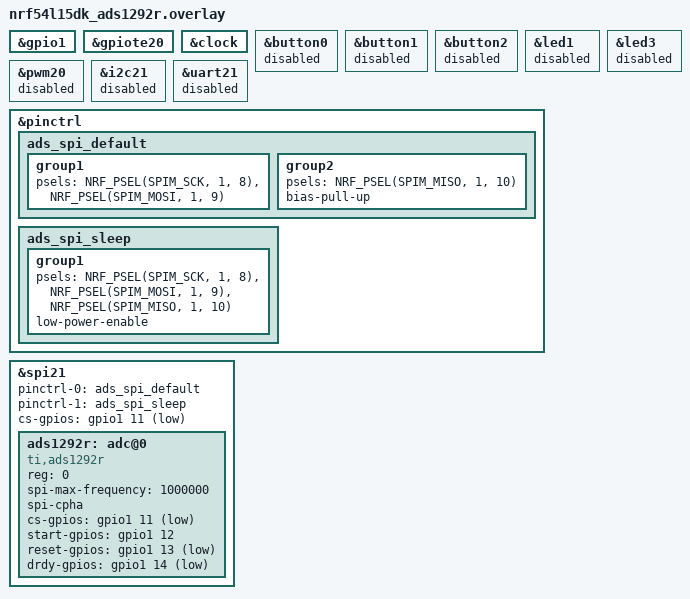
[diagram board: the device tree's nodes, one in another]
#include <zephyr/dt-bindings/gpio/gpio.h>
#include <zephyr/dt-bindings/pinctrl/nrf-pinctrl.h>

/*
 * ADS1292R full test-signal wiring for the Nordic nRF54L15 DK.
 *
 * Configure the DK target voltage to 3V3 in Nordic Board Programmer before
 * connecting the ADS1292R logic pins.
 *
 *   ADS SCK        -> P1.08
 *   ADS DIN/MOSI   -> P1.09
 *   ADS DOUT/MISO  -> P1.10
 *   ADS CS         -> P1.11
 *   ADS START      -> P1.12
 *   ADS PWDN/RESET -> P1.13
 *   ADS DRDY       -> P1.14
 */

&gpio1 { status = "okay"; };
&gpiote20 { status = "okay"; };
&clock { status = "okay"; };

/* These DK functions use pins selected above for ADS signals. */
&button0 { status = "disabled"; };  /* P1.13 / ADS PWDN/RESET */
&button1 { status = "disabled"; };  /* P1.09 / ADS DIN/MOSI */
&button2 { status = "disabled"; };  /* P1.08 / ADS SCK */
&led1 { status = "disabled"; };     /* P1.10 / ADS DOUT/MISO */
&led3 { status = "disabled"; };     /* P1.14 / ADS DRDY */
&pwm20 { status = "disabled"; };

/* spi21 shares this serial block with i2c21/uart21. Keep the owner explicit. */
&i2c21 { status = "disabled"; };
&uart21 { status = "disabled"; };

&pinctrl {
    ads_spi_default: ads_spi_default {
        group1 {
            psels = <NRF_PSEL(SPIM_SCK, 1, 8)>,
                    <NRF_PSEL(SPIM_MOSI, 1, 9)>;
        };
        group2 {
            psels = <NRF_PSEL(SPIM_MISO, 1, 10)>;
            bias-pull-up;
        };
    };

    ads_spi_sleep: ads_spi_sleep {
        group1 {
            psels = <NRF_PSEL(SPIM_SCK, 1, 8)>,
                    <NRF_PSEL(SPIM_MOSI, 1, 9)>,
                    <NRF_PSEL(SPIM_MISO, 1, 10)>;
            low-power-enable;
        };
    };
};

&spi21 {
    status = "okay";
    pinctrl-0 = <&ads_spi_default>;
    pinctrl-1 = <&ads_spi_sleep>;
    pinctrl-names = "default", "sleep";
    cs-gpios = <&gpio1 11 GPIO_ACTIVE_LOW>;

    ads1292r: adc@0 {
        compatible = "ti,ads1292r";
        reg = <0>;
        spi-max-frequency = <1000000>;
        spi-cpha;
        cs-gpios = <&gpio1 11 GPIO_ACTIVE_LOW>;
        start-gpios = <&gpio1 12 GPIO_ACTIVE_HIGH>;
        reset-gpios = <&gpio1 13 GPIO_ACTIVE_LOW>;
        drdy-gpios = <&gpio1 14 GPIO_ACTIVE_LOW>;
    };
};
